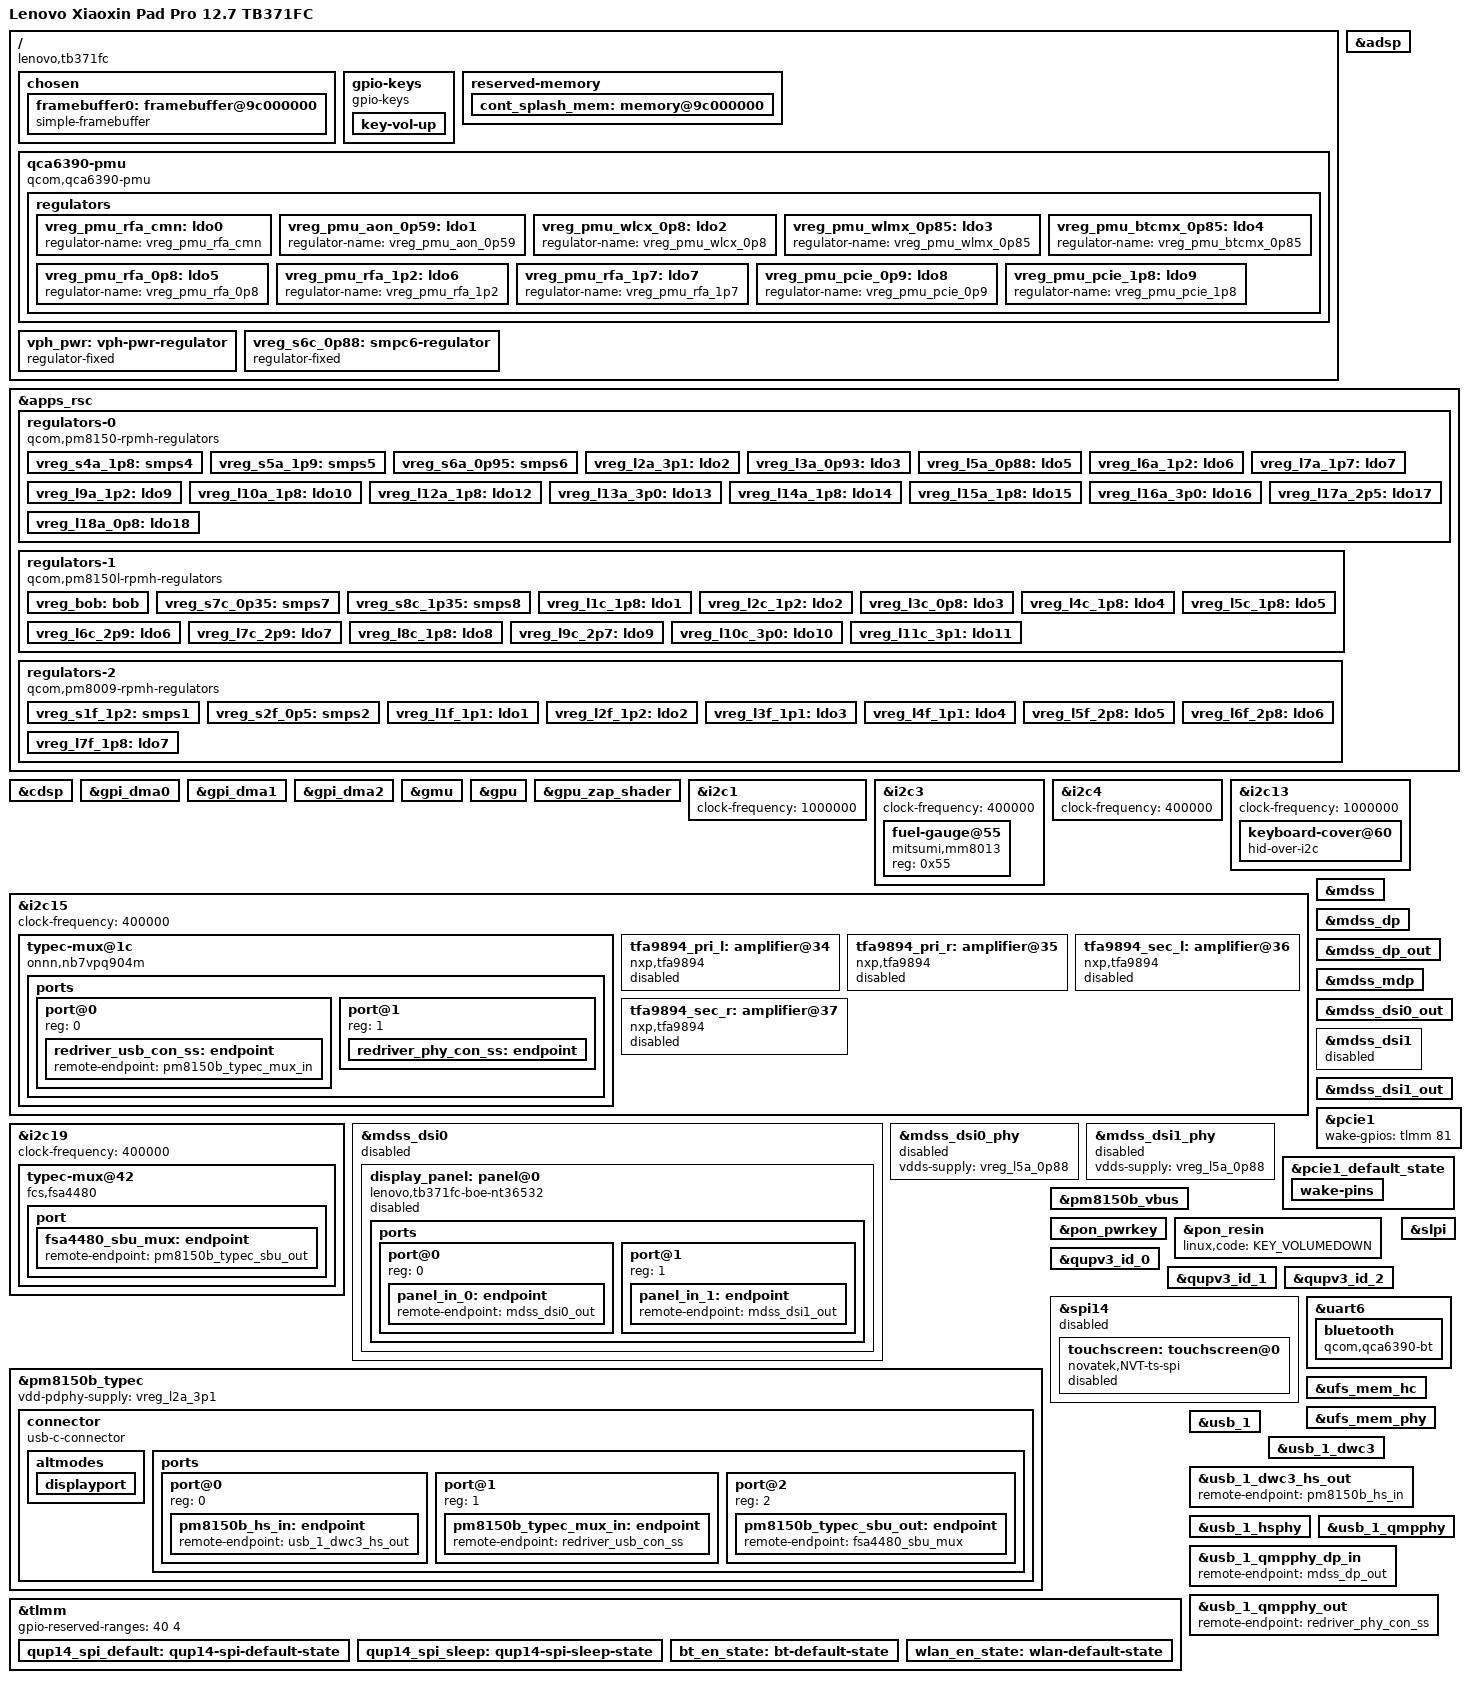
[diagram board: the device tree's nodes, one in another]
// SPDX-License-Identifier: GPL-2.0
/*
 * Copyright (c) 2022, The Linux Foundation. All rights reserved.
 */

/dts-v1/;

#include <dt-bindings/gpio/gpio.h>
#include <dt-bindings/regulator/qcom,rpmh-regulator.h>
#include <dt-bindings/usb/pd.h>
#include "sm8250.dtsi"
#include "pm8150.dtsi"
#include "pm8150b.dtsi"
#include "pm8150l.dtsi"
#include "pm8009.dtsi"

/ {
	model = "Lenovo Xiaoxin Pad Pro 12.7 TB371FC";
	compatible = "lenovo,tb371fc", "qcom,sm8250";
	chassis-type = "tablet";

	qcom,msm-id = <0x164 0x20001>;
	/* The stock TB371FC overlay is board 0xb; use the generic match here. */
	qcom,board-id = <0 0>;

	chosen {
		#address-cells = <2>;
		#size-cells = <2>;
		ranges;

		bootargs = "fw_devlink=permissive clk_ignore_unused pd_ignore_unused";
		stdout-path = "framebuffer0";

		framebuffer0: framebuffer@9c000000 {
			compatible = "simple-framebuffer";
			reg = <0 0x9c000000 0 0x2300000>;
			width = <2944>;
			height = <1840>;
			stride = <(2944 * 4)>;
			format = "a8r8g8b8";
		};
	};

	gpio-keys {
		compatible = "gpio-keys";

		key-vol-up {
			label = "Volume Up";
			linux,code = <KEY_VOLUMEUP>;
			gpios = <&pm8150_gpios 6 GPIO_ACTIVE_LOW>;
			debounce-interval = <15>;
		};
	};

	reserved-memory {
		cont_splash_mem: memory@9c000000 {
			reg = <0x0 0x9c000000 0x0 0x2300000>;
			no-map;
		};
	};

	qca6390-pmu {
		compatible = "qcom,qca6390-pmu";
		pinctrl-names = "default";
		pinctrl-0 = <&bt_en_state>, <&wlan_en_state>;
		vddaon-supply = <&vreg_s6a_0p95>;
		vddpmu-supply = <&vreg_s6a_0p95>;
		vddrfa0p95-supply = <&vreg_s6a_0p95>;
		vddrfa1p3-supply = <&vreg_s8c_1p35>;
		vddrfa1p9-supply = <&vreg_s5a_1p9>;
		vddpcie1p3-supply = <&vreg_s8c_1p35>;
		vddpcie1p9-supply = <&vreg_s5a_1p9>;
		vddio-supply = <&vreg_s4a_1p8>;
		wlan-enable-gpios = <&tlmm 20 GPIO_ACTIVE_HIGH>;
		bt-enable-gpios = <&tlmm 21 GPIO_ACTIVE_HIGH>;

		regulators {
			vreg_pmu_rfa_cmn: ldo0 { regulator-name = "vreg_pmu_rfa_cmn"; };
			vreg_pmu_aon_0p59: ldo1 { regulator-name = "vreg_pmu_aon_0p59"; };
			vreg_pmu_wlcx_0p8: ldo2 { regulator-name = "vreg_pmu_wlcx_0p8"; };
			vreg_pmu_wlmx_0p85: ldo3 { regulator-name = "vreg_pmu_wlmx_0p85"; };
			vreg_pmu_btcmx_0p85: ldo4 { regulator-name = "vreg_pmu_btcmx_0p85"; };
			vreg_pmu_rfa_0p8: ldo5 { regulator-name = "vreg_pmu_rfa_0p8"; };
			vreg_pmu_rfa_1p2: ldo6 { regulator-name = "vreg_pmu_rfa_1p2"; };
			vreg_pmu_rfa_1p7: ldo7 { regulator-name = "vreg_pmu_rfa_1p7"; };
			vreg_pmu_pcie_0p9: ldo8 { regulator-name = "vreg_pmu_pcie_0p9"; };
			vreg_pmu_pcie_1p8: ldo9 { regulator-name = "vreg_pmu_pcie_1p8"; };
		};
	};

	vph_pwr: vph-pwr-regulator {
		compatible = "regulator-fixed";
		regulator-name = "vph_pwr";
		regulator-min-microvolt = <3700000>;
		regulator-max-microvolt = <3700000>;
	};

	/* S6c is really ebi.lvl but it's there for supply map completeness sake. */
	vreg_s6c_0p88: smpc6-regulator {
		compatible = "regulator-fixed";
		regulator-name = "vreg_s6c_0p88";

		regulator-min-microvolt = <880000>;
		regulator-max-microvolt = <880000>;
		regulator-always-on;
		vin-supply = <&vph_pwr>;
	};
};

&adsp {
	status = "okay";
	firmware-name = "qcom/sm8250/lenovo/tb371fc/adsp.mbn";
};

&apps_rsc {
    regulators-0 {
        compatible = "qcom,pm8150-rpmh-regulators";
        qcom,pmic-id = "a";

		vdd-s1-supply = <&vph_pwr>;
		vdd-s2-supply = <&vph_pwr>;
		vdd-s3-supply = <&vph_pwr>;
		vdd-s4-supply = <&vph_pwr>;
		vdd-s5-supply = <&vph_pwr>;
		vdd-s6-supply = <&vph_pwr>;
		vdd-s7-supply = <&vph_pwr>;
		vdd-s8-supply = <&vph_pwr>;
		vdd-s9-supply = <&vph_pwr>;
		vdd-s10-supply = <&vph_pwr>;
		vdd-l1-l8-l11-supply = <&vreg_s6c_0p88>;
		vdd-l2-l10-supply = <&vreg_bob>;
		vdd-l3-l4-l5-l18-supply = <&vreg_s6a_0p95>;
		vdd-l6-l9-supply = <&vreg_s8c_1p35>;
		vdd-l7-l12-l14-l15-supply = <&vreg_s5a_1p9>;
		vdd-l13-l16-l17-supply = <&vreg_bob>;

		/* (S1+S2+S3) - cx.lvl (ARC) */

		vreg_s4a_1p8: smps4 {
			regulator-name = "vreg_s4a_1p8";
			regulator-min-microvolt = <1800000>;
			regulator-max-microvolt = <1920000>;
			regulator-initial-mode = <RPMH_REGULATOR_MODE_HPM>;
		};

		vreg_s5a_1p9: smps5 {
			regulator-name = "vreg_s5a_1p9";
			regulator-min-microvolt = <1900000>;
			regulator-max-microvolt = <2040000>;
			regulator-initial-mode = <RPMH_REGULATOR_MODE_HPM>;
		};

		vreg_s6a_0p95: smps6 {
			regulator-name = "vreg_s6a_0p95";
			regulator-min-microvolt = <950000>;
			regulator-max-microvolt = <1128000>;
			regulator-initial-mode = <RPMH_REGULATOR_MODE_HPM>;
		};

		vreg_l2a_3p1: ldo2 {
			regulator-name = "vreg_l2a_3p1";
			regulator-min-microvolt = <3072000>;
			regulator-max-microvolt = <3072000>;
			regulator-initial-mode = <RPMH_REGULATOR_MODE_HPM>;
		};

		vreg_l3a_0p93: ldo3 {
			regulator-name = "vreg_l3a_0p93";
			regulator-min-microvolt = <928000>;
			regulator-max-microvolt = <932000>;
			regulator-initial-mode = <RPMH_REGULATOR_MODE_HPM>;
		};

		/* L4 - lmx.lvl (ARC) */

		vreg_l5a_0p88: ldo5 {
			regulator-name = "vreg_l5a_0p88";
			regulator-min-microvolt = <880000>;
			regulator-max-microvolt = <880000>;
			regulator-initial-mode = <RPMH_REGULATOR_MODE_HPM>;
		};

		vreg_l6a_1p2: ldo6 {
			regulator-name = "vreg_l6a_1p2";
			regulator-min-microvolt = <1200000>;
			regulator-max-microvolt = <1200000>;
			regulator-initial-mode = <RPMH_REGULATOR_MODE_HPM>;
		};

		vreg_l7a_1p7: ldo7 {
			regulator-name = "vreg_l7a_1p7";
			regulator-min-microvolt = <1704000>;
			regulator-max-microvolt = <1800000>;
			regulator-initial-mode = <RPMH_REGULATOR_MODE_HPM>;
		};

		vreg_l9a_1p2: ldo9 {
			regulator-name = "vreg_l9a_1p2";
			regulator-min-microvolt = <1200000>;
			regulator-max-microvolt = <1200000>;
			regulator-initial-mode = <RPMH_REGULATOR_MODE_HPM>;
		};

		vreg_l10a_1p8: ldo10 {
			regulator-name = "vreg_l10a_1p8";
			regulator-min-microvolt = <1800000>;
			regulator-max-microvolt = <2960000>;
			regulator-initial-mode = <RPMH_REGULATOR_MODE_HPM>;
		};

		/* L11 - lcx.lvl (ARC) */

		vreg_l12a_1p8: ldo12 {
			regulator-name = "vreg_l12a_1p8";
			regulator-min-microvolt = <1800000>;
			regulator-max-microvolt = <1800000>;
			regulator-initial-mode = <RPMH_REGULATOR_MODE_HPM>;
		};

		vreg_l13a_3p0: ldo13 {
			regulator-name = "vreg_l13a_3p0";
			regulator-min-microvolt = <3008000>;
			regulator-max-microvolt = <3008000>;
			regulator-initial-mode = <RPMH_REGULATOR_MODE_HPM>;
		};

		vreg_l14a_1p8: ldo14 {
			regulator-name = "vreg_l14a_1p8";
			regulator-min-microvolt = <1800000>;
			regulator-max-microvolt = <1880000>;
			regulator-initial-mode = <RPMH_REGULATOR_MODE_HPM>;
		};

		vreg_l15a_1p8: ldo15 {
			regulator-name = "vreg_l15a_1p8";
			regulator-min-microvolt = <1800000>;
			regulator-max-microvolt = <1800000>;
			regulator-initial-mode = <RPMH_REGULATOR_MODE_HPM>;
		};

		vreg_l16a_3p0: ldo16 {
			regulator-name = "vreg_l16a_3p0";
			regulator-min-microvolt = <3024000>;
			regulator-max-microvolt = <3304000>;
			regulator-initial-mode = <RPMH_REGULATOR_MODE_HPM>;
		};

		vreg_l17a_2p5: ldo17 {
			regulator-name = "vreg_l17a_2p5";
			regulator-min-microvolt = <2496000>;
			regulator-max-microvolt = <3008000>;
			regulator-initial-mode = <RPMH_REGULATOR_MODE_HPM>;
		};

		vreg_l18a_0p8: ldo18 {
			regulator-name = "vreg_l18a_0p8";
			regulator-min-microvolt = <800000>;
			regulator-max-microvolt = <920000>;
			regulator-initial-mode = <RPMH_REGULATOR_MODE_HPM>;
		};
	};

	/*
	 * Remaining regulators that are not yet supported:
	 * OLEDB: 4925000-8100000
	 * ab: 4600000-6100000
	 * ibb: 800000-5400000
	 */

	regulators-1 {
		compatible = "qcom,pm8150l-rpmh-regulators";
		qcom,pmic-id = "c";

		vdd-s1-supply = <&vph_pwr>;
		vdd-s2-supply = <&vph_pwr>;
		vdd-s3-supply = <&vph_pwr>;
		vdd-s4-supply = <&vph_pwr>;
		vdd-s5-supply = <&vph_pwr>;
		vdd-s6-supply = <&vph_pwr>;
		vdd-s7-supply = <&vph_pwr>;
		vdd-s8-supply = <&vph_pwr>;
		vdd-l1-l8-supply = <&vreg_s4a_1p8>;
		vdd-l2-l3-supply = <&vreg_s8c_1p35>;
		vdd-l4-l5-l6-supply = <&vreg_bob>;
		vdd-l7-l11-supply = <&vreg_bob>;
		vdd-l9-l10-supply = <&vreg_bob>;
		vdd-bob-supply = <&vph_pwr>;

		vreg_bob: bob {
			regulator-name = "vreg_bob";
			regulator-min-microvolt = <3008000>;
			regulator-max-microvolt = <3960000>;
			regulator-initial-mode = <RPMH_REGULATOR_MODE_AUTO>;
		};

		/*
		 * S1-S6 are ARCs:
		 * (S1+S2) - gfx.lvl,
		 * S3 - mx.lvl,
		 * (S4+S5) - mmcx.lvl,
		 * S6 - ebi.lvl
		 */

		vreg_s7c_0p35: smps7 {
			regulator-name = "vreg_s7c_0p35";
			regulator-min-microvolt = <348000>;
			regulator-max-microvolt = <1000000>;
			regulator-initial-mode = <RPMH_REGULATOR_MODE_HPM>;
		};

		vreg_s8c_1p35: smps8 {
			regulator-name = "vreg_s8c_1p4";
			regulator-min-microvolt = <1350000>;
			regulator-max-microvolt = <1400000>;
			regulator-initial-mode = <RPMH_REGULATOR_MODE_HPM>;
		};

		vreg_l1c_1p8: ldo1 {
			regulator-name = "vreg_l1c_1p8";
			regulator-min-microvolt = <1800000>;
			regulator-max-microvolt = <1800000>;
			regulator-initial-mode = <RPMH_REGULATOR_MODE_HPM>;
		};

		vreg_l2c_1p2: ldo2 {
			regulator-name = "vreg_l2c_1p2";
			regulator-min-microvolt = <1200000>;
			regulator-max-microvolt = <1304000>;
			regulator-initial-mode = <RPMH_REGULATOR_MODE_HPM>;
		};

		vreg_l3c_0p8: ldo3 {
			regulator-name = "vreg_l3c_0p8";
			regulator-min-microvolt = <800000>;
			regulator-max-microvolt = <1200000>;
			regulator-initial-mode = <RPMH_REGULATOR_MODE_HPM>;
		};

		vreg_l4c_1p8: ldo4 {
			regulator-name = "vreg_l4c_1p8";
			regulator-min-microvolt = <1800000>;
			regulator-max-microvolt = <2800000>;
			regulator-initial-mode = <RPMH_REGULATOR_MODE_HPM>;
		};

		vreg_l5c_1p8: ldo5 {
			regulator-name = "vreg_l5c_1p8";
			regulator-min-microvolt = <1800000>;
			regulator-max-microvolt = <2800000>;
			regulator-initial-mode = <RPMH_REGULATOR_MODE_HPM>;
		};

		vreg_l6c_2p9: ldo6 {
			regulator-name = "vreg_l6c_2p9";
			regulator-min-microvolt = <1800000>;
			regulator-max-microvolt = <2960000>;
			regulator-initial-mode = <RPMH_REGULATOR_MODE_HPM>;
			regulator-allowed-modes = <RPMH_REGULATOR_MODE_LPM
						   RPMH_REGULATOR_MODE_HPM>;
			regulator-allow-set-load;
		};

		vreg_l7c_2p9: ldo7 {
			regulator-name = "vreg_l7c_2p9";
			regulator-min-microvolt = <2856000>;
			regulator-max-microvolt = <3104000>;
			regulator-initial-mode = <RPMH_REGULATOR_MODE_HPM>;
		};

		vreg_l8c_1p8: ldo8 {
			regulator-name = "vreg_l8c_1p8";
			regulator-min-microvolt = <1800000>;
			regulator-max-microvolt = <1800000>;
			regulator-initial-mode = <RPMH_REGULATOR_MODE_HPM>;
		};

		vreg_l9c_2p7: ldo9 {
			regulator-name = "vreg_l9c_2p7";
			regulator-min-microvolt = <2704000>;
			regulator-max-microvolt = <2960000>;
			regulator-initial-mode = <RPMH_REGULATOR_MODE_HPM>;
			regulator-allowed-modes = <RPMH_REGULATOR_MODE_LPM
						   RPMH_REGULATOR_MODE_HPM>;
			regulator-allow-set-load;
		};

		vreg_l10c_3p0: ldo10 {
			regulator-name = "vreg_l10c_3p0";
			regulator-min-microvolt = <3000000>;
			regulator-max-microvolt = <3312000>;
			regulator-initial-mode = <RPMH_REGULATOR_MODE_HPM>;
		};

		vreg_l11c_3p1: ldo11 {
			regulator-name = "vreg_l11c_3p1";
			regulator-min-microvolt = <3104000>;
			regulator-max-microvolt = <3304000>;
			regulator-initial-mode = <RPMH_REGULATOR_MODE_HPM>;
		};
	};

	regulators-2 {
		compatible = "qcom,pm8009-rpmh-regulators";
		qcom,pmic-id = "f";

		vdd-s1-supply = <&vph_pwr>;
		vdd-s2-supply = <&vreg_bob>;
		vdd-l2-supply = <&vreg_s8c_1p35>;
		vdd-l5-l6-supply = <&vreg_bob>;
		vdd-l7-supply = <&vreg_s4a_1p8>;

		vreg_s1f_1p2: smps1 {
			regulator-name = "vreg_s1f_1p2";
			regulator-min-microvolt = <1200000>;
			regulator-max-microvolt = <1200000>;
			regulator-initial-mode = <RPMH_REGULATOR_MODE_HPM>;
		};

		vreg_s2f_0p5: smps2 {
			regulator-name = "vreg_s2f_0p5";
			regulator-min-microvolt = <512000>;
			regulator-max-microvolt = <1100000>;
			regulator-initial-mode = <RPMH_REGULATOR_MODE_HPM>;
		};

		vreg_l1f_1p1: ldo1 {
			regulator-name = "vreg_l1f_1p1";
			regulator-min-microvolt = <1104000>;
			regulator-max-microvolt = <1200000>;
			regulator-initial-mode = <RPMH_REGULATOR_MODE_HPM>;
		};

		vreg_l2f_1p2: ldo2 {
			regulator-name = "vreg_l2f_1p2";
			regulator-min-microvolt = <1200000>;
			regulator-max-microvolt = <1200000>;
			regulator-initial-mode = <RPMH_REGULATOR_MODE_HPM>;
		};

		vreg_l3f_1p1: ldo3 {
			regulator-name = "vreg_l3f_1p1";
			regulator-min-microvolt = <1056000>;
			regulator-max-microvolt = <1200000>;
			regulator-initial-mode = <RPMH_REGULATOR_MODE_HPM>;
		};

		vreg_l4f_1p1: ldo4 {
			regulator-name = "vreg_l4f_1p1";
			regulator-min-microvolt = <1096000>;
			regulator-max-microvolt = <1304000>;
			regulator-initial-mode = <RPMH_REGULATOR_MODE_HPM>;
		};

		vreg_l5f_2p8: ldo5 {
			regulator-name = "vreg_l5f_2p8";
			regulator-min-microvolt = <2800000>;
			regulator-max-microvolt = <3000000>;
			regulator-initial-mode = <RPMH_REGULATOR_MODE_HPM>;
		};

		vreg_l6f_2p8: ldo6 {
			regulator-name = "vreg_l6f_2p8";
			regulator-min-microvolt = <2800000>;
			regulator-max-microvolt = <3000000>;
			regulator-initial-mode = <RPMH_REGULATOR_MODE_HPM>;
		};

		vreg_l7f_1p8: ldo7 {
			regulator-name = "vreg_l7f_1p8";
			regulator-min-microvolt = <1800000>;
			regulator-max-microvolt = <1800000>;
			regulator-initial-mode = <RPMH_REGULATOR_MODE_HPM>;
		};
	};
};

&cdsp {
	status = "okay";
	firmware-name = "qcom/sm8250/lenovo/tb371fc/cdsp.mbn";
};

&gpi_dma0 {
	status = "okay";
};

&gpi_dma1 {
	status = "okay";
};

&gpi_dma2 {
	status = "okay";
};

&gmu {
	status = "okay";
};

&gpu {
	status = "okay";
};

&gpu_zap_shader {
	firmware-name = "qcom/sm8250/lenovo/tb371fc/a650_zap.mbn";
};

&i2c1 {
	status = "okay";
	clock-frequency = <1000000>;

	/* hid-over-i2c ptp @ 60 */
};

&i2c3 {
	status = "okay";
	clock-frequency = <400000>;

	fuel-gauge@55 {
		compatible = "mitsumi,mm8013";
		reg = <0x55>;
	};
};

&i2c4 {
	status = "okay";
	clock-frequency = <400000>;

	/* onnn,redriver (DP out) @ 19 */
	/* hid-over-i2c keyboard @ 61 */
};

&i2c13 {
	status = "okay";
	clock-frequency = <1000000>;

	keyboard-cover@60 {
		compatible = "hid-over-i2c";
		reg = <0x60>;

		interrupt-parent = <&tlmm>;
		interrupts = <110 IRQ_TYPE_LEVEL_LOW>;

		/*
		 * The Lenovo keyboard MCU only answers after both lines have
		 * been sequenced.  Physical high deasserts reset and wakes it.
		 */
		reset-gpios = <&tlmm 114 GPIO_ACTIVE_LOW>;
		wake-gpios = <&tlmm 108 GPIO_ACTIVE_HIGH>;
		hid-descr-addr = <0x1>;
		post-reset-deassert-delay-ms = <120>;
	};
};

&i2c15 {
	status = "okay";
	clock-frequency = <400000>;

	typec-mux@1c {
		compatible = "onnn,nb7vpq904m";
		reg = <0x1c>;

		vcc-supply = <&vreg_s4a_1p8>;
		retimer-switch;
		orientation-switch;

		ports {
			#address-cells = <1>;
			#size-cells = <0>;

			port@0 {
				reg = <0>;

				redriver_usb_con_ss: endpoint {
					remote-endpoint = <&pm8150b_typec_mux_in>;
				};
			};

			port@1 {
				reg = <1>;

				redriver_phy_con_ss: endpoint {
					remote-endpoint = <&usb_1_qmpphy_out>;
					data-lanes = <0 1 2 3>;
				};
			};
		};
	};

	/*
	 * Four TFA9894 N1A1 smart amplifiers share primary TDM. Stock firmware
	 * contains different QS and YC acoustic containers; keep every amplifier
	 * disabled until the fitted speaker variant can be identified in Android.
	 */
	tfa9894_pri_l: amplifier@34 {
		compatible = "nxp,tfa9894";
		reg = <0x34>;
		#sound-dai-cells = <1>;
		reset-gpios = <&tlmm 115 GPIO_ACTIVE_HIGH>;
		reset-polarity = <1>;
		sound-name-prefix = "Primary Left";
		status = "disabled";
	};

	tfa9894_pri_r: amplifier@35 {
		compatible = "nxp,tfa9894";
		reg = <0x35>;
		#sound-dai-cells = <1>;
		reset-gpios = <&tlmm 117 GPIO_ACTIVE_HIGH>;
		reset-polarity = <1>;
		sound-name-prefix = "Primary Right";
		status = "disabled";
	};

	tfa9894_sec_l: amplifier@36 {
		compatible = "nxp,tfa9894";
		reg = <0x36>;
		#sound-dai-cells = <1>;
		reset-gpios = <&tlmm 118 GPIO_ACTIVE_HIGH>;
		reset-polarity = <1>;
		sound-name-prefix = "Secondary Left";
		status = "disabled";
	};

	tfa9894_sec_r: amplifier@37 {
		compatible = "nxp,tfa9894";
		reg = <0x37>;
		#sound-dai-cells = <1>;
		reset-gpios = <&tlmm 116 GPIO_ACTIVE_HIGH>;
		reset-polarity = <1>;
		sound-name-prefix = "Secondary Right";
		status = "disabled";
	};
};

&i2c19 {
	status = "okay";
	clock-frequency = <400000>;

	typec-mux@42 {
		compatible = "fcs,fsa4480";
		reg = <0x42>;
		mode-switch;
		orientation-switch;

		port {
			fsa4480_sbu_mux: endpoint {
				remote-endpoint = <&pm8150b_typec_sbu_out>;
			};
		};
	};
};

&mdss {
	status = "okay";
};

&mdss_dp {
	status = "okay";
};

&mdss_dp_out {
	data-lanes = <0 1>;
	remote-endpoint = <&usb_1_qmpphy_dp_in>;
};

&mdss_mdp {
	assigned-clocks = <&dispcc DISP_CC_MDSS_VSYNC_CLK>,
			  <&dispcc DISP_CC_MDSS_MDP_CLK>;
	assigned-clock-rates = <19200000>, <460000000>;
};

/*
 * The native panel path is intentionally disabled for the first simplefb
 * bring-up. TB371FC ships with either a BOE or Tianma NT36532 command table;
 * the exact fitted variant must be identified before this node is enabled.
 */
&mdss_dsi0 {
	vdda-supply = <&vreg_l9a_1p2>;
	qcom,dual-dsi-mode;
	qcom,sync-dual-dsi;
	qcom,master-dsi;
	status = "disabled";

	display_panel: panel@0 {
		compatible = "lenovo,tb371fc-boe-nt36532", "novatek,nt36523";
		reg = <0>;
		vddio-supply = <&vreg_l14a_1p8>;
		reset-gpios = <&tlmm 69 GPIO_ACTIVE_LOW>;
		rotation = <270>;
		status = "disabled";

		ports {
			#address-cells = <1>;
			#size-cells = <0>;

			port@0 {
				reg = <0>;

				panel_in_0: endpoint {
					remote-endpoint = <&mdss_dsi0_out>;
				};
			};

			port@1 {
				reg = <1>;

				panel_in_1: endpoint {
					remote-endpoint = <&mdss_dsi1_out>;
				};
			};
		};
	};
};

&mdss_dsi0_out {
	data-lanes = <0 1 2 3>;
	remote-endpoint = <&panel_in_0>;
};

&mdss_dsi0_phy {
	vdds-supply = <&vreg_l5a_0p88>;
	status = "disabled";
};

&mdss_dsi1 {
	vdda-supply = <&vreg_l9a_1p2>;
	qcom,dual-dsi-mode;
	qcom,sync-dual-dsi;
	assigned-clock-parents = <&mdss_dsi0_phy DSI_BYTE_PLL_CLK>,
				 <&mdss_dsi0_phy DSI_PIXEL_PLL_CLK>;
	status = "disabled";
};

&mdss_dsi1_out {
	data-lanes = <0 1 2 3>;
	remote-endpoint = <&panel_in_1>;
};

&mdss_dsi1_phy {
	vdds-supply = <&vreg_l5a_0p88>;
	status = "disabled";
};

&pcie1 {
	wake-gpios = <&tlmm 81 GPIO_ACTIVE_HIGH>;
};

&pcie1_default_state {
	wake-pins {
		pins = "gpio81";
		/delete-property/ bias-pull-up;
		bias-disable;
	};
};

&pm8150b_typec {
	status = "okay";
	vdd-pdphy-supply = <&vreg_l2a_3p1>;

	connector {
		compatible = "usb-c-connector";
		op-sink-microwatt = <10000000>;
		power-role = "dual";
		data-role = "dual";
		self-powered;

		source-pdos = <PDO_FIXED(5000, 3000,
				 PDO_FIXED_DUAL_ROLE |
				 PDO_FIXED_USB_COMM |
				 PDO_FIXED_DATA_SWAP)>;

		sink-pdos = <PDO_FIXED(5000, 3000,
				      PDO_FIXED_DUAL_ROLE |
				      PDO_FIXED_USB_COMM |
				      PDO_FIXED_DATA_SWAP)
			     PDO_VAR(5000, 12000, 5000)>;

		altmodes {
			displayport {
				svid = /bits/ 16 <0xff01>;
				vdo = <0x00001c46>;
			};
		};

		ports {
			#address-cells = <1>;
			#size-cells = <0>;

			port@0 {
				reg = <0>;

				pm8150b_hs_in: endpoint {
					remote-endpoint = <&usb_1_dwc3_hs_out>;
				};
			};

			port@1 {
				reg = <1>;

				pm8150b_typec_mux_in: endpoint {
					remote-endpoint = <&redriver_usb_con_ss>;
				};
			};

			port@2 {
				reg = <2>;

				pm8150b_typec_sbu_out: endpoint {
					remote-endpoint = <&fsa4480_sbu_mux>;
				};
			};
		};
	};
};

&pm8150b_vbus {
	regulator-min-microamp = <500000>;
	regulator-max-microamp = <3000000>;
	status = "okay";
};

&pon_pwrkey {
	status = "okay";
};

&pon_resin {
	status = "okay";

	linux,code = <KEY_VOLUMEDOWN>;
};

&qupv3_id_0 {
	status = "okay";
};

&qupv3_id_1 {
	status = "okay";
};

&qupv3_id_2 {
	status = "okay";
};

/*
 * Stock ZUI uses QUPv3 SE14 for the Novatek NT36532 touch controller and
 * AP500U pen digitizer. Firmware selection and the NT36532 auto-copy loader
 * are implemented, but keep this disabled until a temporary boot validates
 * reset polarity, IRQ signalling and firmware loading on the real hardware.
 */
&spi14 {
	pinctrl-names = "default", "sleep";
	pinctrl-0 = <&qup14_spi_default>;
	pinctrl-1 = <&qup14_spi_sleep>;
	status = "disabled";

	touchscreen: touchscreen@0 {
		compatible = "novatek,NVT-ts-spi";
		reg = <0>;
		spi-max-frequency = <9600000>;

		reset-gpios = <&tlmm 56 GPIO_ACTIVE_LOW>;
		irq-gpios = <&tlmm 68 GPIO_ACTIVE_HIGH>;
		panel-id-gpios = <&tlmm 82 GPIO_ACTIVE_HIGH>;

		novatek,pen-support;
		novatek,stylus-resol-double;
		novatek,super-resolution = <10>;
		novatek,swrst-n8-addr = <0x1fb43e>;
		novatek,boe-firmware-name =
			"lenovo/tb371fc/novatek_ts_fw_boe_6.bin";
		novatek,tianma-firmware-name =
			"lenovo/tb371fc/novatek_ts_tm_fw_6.bin";

		status = "disabled";
	};
};

&slpi {
	status = "okay";
	firmware-name = "qcom/sm8250/lenovo/tb371fc/slpi.mbn";
};

&tlmm {
	gpio-reserved-ranges = <40 4>;

	qup14_spi_default: qup14-spi-default-state {
		pins = "gpio40", "gpio41", "gpio42", "gpio43";
		function = "qup14";
		drive-strength = <6>;
		bias-disable;
	};

	qup14_spi_sleep: qup14-spi-sleep-state {
		pins = "gpio40", "gpio41", "gpio42", "gpio43";
		function = "gpio";
		drive-strength = <6>;
		bias-disable;
	};

	bt_en_state: bt-default-state {
		pins = "gpio21";
		function = "gpio";
		drive-strength = <16>;
		output-low;
		bias-pull-up;
	};

	wlan_en_state: wlan-default-state {
		pins = "gpio20";
		function = "gpio";
		drive-strength = <16>;
		output-low;
		bias-pull-up;
	};
};

&uart6 {
	status = "okay";

	bluetooth {
		compatible = "qcom,qca6390-bt";
		vddrfacmn-supply = <&vreg_pmu_rfa_cmn>;
		vddaon-supply = <&vreg_pmu_aon_0p59>;
		vddbtcmx-supply = <&vreg_pmu_btcmx_0p85>;
		vddrfa0p8-supply = <&vreg_pmu_rfa_0p8>;
		vddrfa1p2-supply = <&vreg_pmu_rfa_1p2>;
		vddrfa1p7-supply = <&vreg_pmu_rfa_1p7>;
	};
};

&ufs_mem_hc {
	status = "okay";

	vcc-supply = <&vreg_l17a_2p5>;
	vcc-max-microamp = <800000>;
	vccq-supply = <&vreg_l6a_1p2>;
	vccq-max-microamp = <800000>;
	vccq2-supply = <&vreg_s4a_1p8>;
	vccq2-max-microamp = <800000>;
};

&ufs_mem_phy {
	status = "okay";

	vdda-phy-supply = <&vreg_l5a_0p88>;
	vdda-pll-supply = <&vreg_l9a_1p2>;
};

&usb_1 {
	status = "okay";
};

&usb_1_dwc3 {
	dr_mode = "otg";
	usb-role-switch;
};

&usb_1_dwc3_hs_out {
	remote-endpoint = <&pm8150b_hs_in>;
};

&usb_1_hsphy {
	status = "okay";

	vdda-pll-supply = <&vreg_l5a_0p88>;
	vdda18-supply = <&vreg_l12a_1p8>;
	vdda33-supply = <&vreg_l2a_3p1>;
};

&usb_1_qmpphy {
	status = "okay";

	vdda-phy-supply = <&vreg_l9a_1p2>;
	vdda-pll-supply = <&vreg_l18a_0p8>;
};

&usb_1_qmpphy_dp_in {
	remote-endpoint = <&mdss_dp_out>;
};

&usb_1_qmpphy_out {
	remote-endpoint = <&redriver_phy_con_ss>;
};
